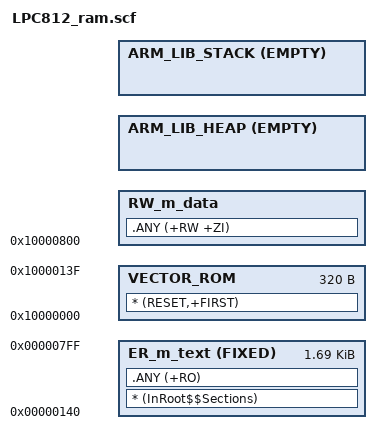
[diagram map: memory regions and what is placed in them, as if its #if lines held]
#! armcc -E
/*
** ###################################################################
**     Processors:          LPC812M101JD20
**                          LPC812M101JDH16
**                          LPC812M101JDH20
**                          LPC812M101JTB16
**
**     Compiler:            Keil ARM C/C++ Compiler
**     Reference manual:    LPC81x User manual Rev.1.6  2 April 2014
**     Version:             rev. 1.0, 2017-10-17
**     Build:               b180801
**
**     Abstract:
**         Linker file for the Keil ARM C/C++ Compiler
**
**     Copyright 2016 Freescale Semiconductor, Inc.
**     Copyright 2016-2018 NXP
**
**     SPDX-License-Identifier: BSD-3-Clause
**
**     http:                 www.nxp.com
**     mail:                 support@nxp.com
**
** ###################################################################
*/


/* Sizes */
#if (defined(__stack_size__))
  #define Stack_Size                   __stack_size__
#else
  #define Stack_Size                   0x0400
#endif

#if (defined(__heap_size__))
  #define Heap_Size                    __heap_size__
#else
  #define Heap_Size                    0x0400
#endif

#define  m_interrupts_start            0x10000000
#define  m_interrupts_size             0x00000140

#define  m_text_start                  0x00000140
#define  m_text_size                   0x000006C0

#define  m_data_start                  0x10000800
#define  m_data_size                   0x00000800

LR_m_text m_text_start m_text_size {   ; load region size_region
  ER_m_text m_text_start FIXED m_text_size { ; load address = execution address
    * (InRoot$$Sections)
    .ANY (+RO)
  }

  RW_m_data m_data_start m_data_size-Stack_Size-Heap_Size { ; RW data
    .ANY (+RW +ZI)
  }
  ARM_LIB_HEAP +0 EMPTY Heap_Size {    ; Heap region growing up
  }
  ARM_LIB_STACK m_data_start+m_data_size EMPTY -Stack_Size { ; Stack region growing down
  }
}

LR_m_interrupts m_interrupts_start m_interrupts_size {
  VECTOR_ROM m_interrupts_start m_interrupts_size { ; load address = execution address
    * (RESET,+FIRST)
  }
}
